AUTOSAR XML (schema 00050)
standard types defined: Boolean
package /ARRoot
  trigger-interface:
    trigger AutomaticDoorUnlockLeftTrigger
    trigger AutomaticDoorUnlockRightTrigger
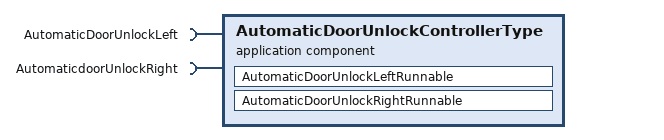
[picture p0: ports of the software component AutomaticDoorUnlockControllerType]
  application sw component type AutomaticDoorUnlockControllerType
    require port AutomaticDoorUnlockLeft
    require port AutomaticdoorUnlockRight
    behavior AutomaticDoorUnlockIB
      runnable AutomaticDoorUnlockLeftRunnable: synchronous-server-call-point=AutomaticDoorUnlockLeft.
      runnable AutomaticDoorUnlockRightRunnable: synchronous-server-call-point=AutomaticdoorUnlockRight.
  swc implementation AutomaticDoorUnlockImpFile: programming-language=C, behavior=AutomaticDoorUnlockControllerType/AutomaticDoorUnlockIB
  swc implementation AutomaticDoorUnlockLeft: programming-language=C
  client server interface AutomaticDoorUnlockLeftCSIF: client-server-operation
  client server interface AutomaticDoorUnlockRightCSIF: client-server-operation
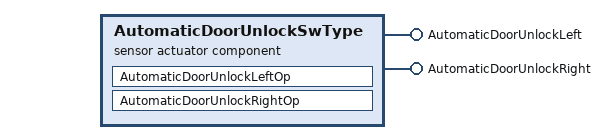
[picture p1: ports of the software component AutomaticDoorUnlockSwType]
  sensor actuator sw component type AutomaticDoorUnlockSwType
    provide port AutomaticDoorUnlockLeft
    provide port AutomaticDoorUnlockRight
    behavior AutomaticDoorUnlockIB
      runnable AutomaticDoorUnlockLeftOp: external-triggering-point=AutomaticDoorUnlockLeft.AutomaticDoorUnlockLeftTrigger
      runnable AutomaticDoorUnlockRightOp: external-triggering-point=AutomaticDoorUnlockRight.AutomaticDoorUnlockRightTrigger
